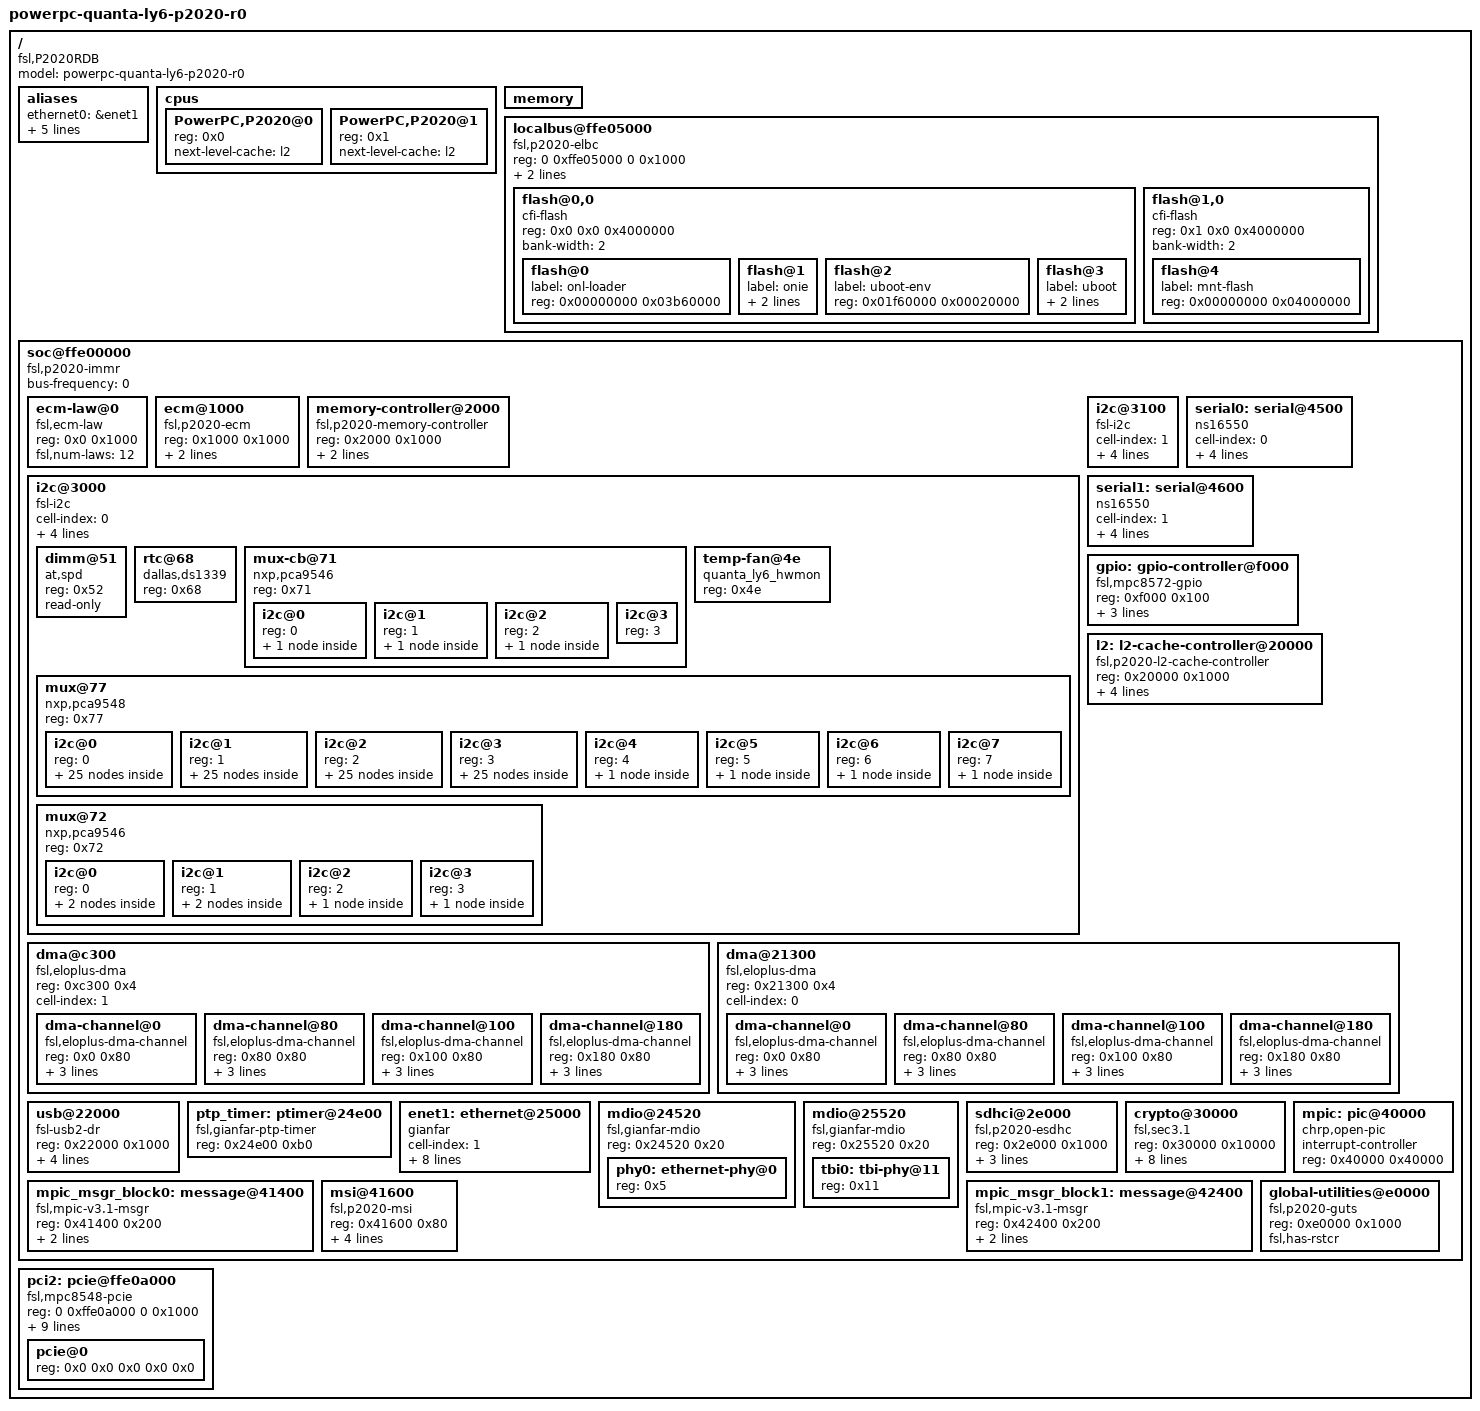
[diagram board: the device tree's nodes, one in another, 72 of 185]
/*
 * <bsn.cl fy=2013 v=gpl>
 * 
 *		Copyright 2013, 2014 BigSwitch Networks, Inc.		
 * 
 * This program is free software; you can redistribute it
 * and/or modify it under  the terms ofthe GNU General Public License as
 * published by the Free Software Foundation;  either version 2 of the  License,
 * or (at your option) any later version.
 * 
 * 
 * </bsn.cl>
 *
 *
 * Device tree for the Quanta LY6 P2020.
 *
 */


/dts-v1/;

/ {
	model = "powerpc-quanta-ly6-p2020-r0";
	compatible = "fsl,P2020RDB";
	#address-cells = <2>;
	#size-cells = <2>;

	aliases {
		ethernet0 = &enet1;
		serial0 = &serial0;
		serial1 = &serial1;
		pci2 = &pci2;
		mpic-msgr-block0 = &mpic_msgr_block0;
		mpic-msgr-block1 = &mpic_msgr_block1;
	};

	cpus {
		#address-cells = <1>;
		#size-cells = <0>;

		PowerPC,P2020@0 {
			device_type = "cpu";
			reg = <0x0>;
			next-level-cache = <&l2>;
		};

		PowerPC,P2020@1 {
			device_type = "cpu";
			reg = <0x1>;
			next-level-cache = <&l2>;
		};
	};

	memory {
		device_type = "memory";
	};

	localbus@ffe05000 {
		#address-cells = <2>;
		#size-cells = <1>;
		compatible = "fsl,p2020-elbc", "fsl,elbc", "simple-bus";
		reg = <0 0xffe05000 0 0x1000>;
		interrupts = <19 2>;
		interrupt-parent = <&mpic>;

		ranges = <0x0 0x0 0x0 0xec000000 0x4000000
			  0x1 0x0 0x0 0xe8000000 0x4000000>;

		flash@0,0 {
			#address-cells = <1>;
			#size-cells = <1>;
			compatible = "cfi-flash";
			reg = <0x0 0x0 0x4000000>;
			bank-width = <2>;

			/*
 			 * ONIE flash layout (reverse-engineered:
			 * - one ~64MiB loader partition
			 * - 4 MiB onie partition
			 * - uboot-env and uboot
			 * - 64MiB leftover space for jffs2
			 *
			 */

			flash@0 {
				label = "onl-loader";
				reg = <0x00000000 0x03b60000>;
			};

			flash@1 {
				label = "onie";
				reg = <0x01b60000 0x00400000>;
				read-only;
			};

			flash@2 {
				label = "uboot-env";
				reg = <0x01f60000 0x00020000>;
			};

			flash@3 {
				label = "uboot";
				reg = <0x01f80000 0x00080000>;
				read-only;
			};

		};

		flash@1,0 {
			#address-cells = <1>;
			#size-cells = <1>;
			compatible = "cfi-flash";
			reg = <0x1 0x0 0x4000000>;
			bank-width = <2>;

			flash@4 {
				label = "mnt-flash";
				reg = <0x00000000 0x04000000>;
			};
		};
	};

	soc@ffe00000 {
		#address-cells = <1>;
		#size-cells = <1>;
		device_type = "soc";
		compatible = "fsl,p2020-immr", "simple-bus";
		ranges = <0x0  0x0 0xffe00000 0x100000>;
		bus-frequency = <0>;

		ecm-law@0 {
			compatible = "fsl,ecm-law";
			reg = <0x0 0x1000>;
			fsl,num-laws = <12>;
		};

		ecm@1000 {
			compatible = "fsl,p2020-ecm", "fsl,ecm";
			reg = <0x1000 0x1000>;
			interrupts = <17 2>;
			interrupt-parent = <&mpic>;
		};

		memory-controller@2000 {
			compatible = "fsl,p2020-memory-controller";
			reg = <0x2000 0x1000>;
			interrupt-parent = <&mpic>;
			interrupts = <18 2>;
		};

		i2c@3000 {
			#address-cells = <1>;
			#size-cells = <0>;
			cell-index = <0>;
			compatible = "fsl-i2c";
			reg = <0x3000 0x100>;
			interrupts = <43 2>;
			interrupt-parent = <&mpic>;
			dfsrr;

			dimm@51 {
				compatible = "at,spd";
				reg = <0x52>;
				read-only;
			};

			rtc@68 {
				compatible = "dallas,ds1339";
				reg = <0x68>;
			};

			mux-cb@71 {
				compatible = "nxp,pca9546";
				reg = <0x71>;
				#address-cells = <1>;
				#size-cells = <0>;

				i2c@0 {
					#address-cells = <1>;
					#size-cells = <0>;
					reg = <0>;

					gpio-cb-9555@20 {
						compatible = "nxp,pca9555";
						reg = <0x20>;
						#gpio-cells = <2>;
						gpio-controller;
					};
				};

				i2c@1 {
					#address-cells = <1>;
					#size-cells = <0>;
					reg = <1>;

					eeprom-cb@53 {
						compatible = "at,24c02";
						reg = <0x53>;
						read-only;
					};
				};

				i2c@2 {
					#address-cells = <1>;
					#size-cells = <0>;
					reg = <2>;

					gpio-cb-9554@21 {
						compatible = "nxp,pca9554";
						reg = <0x21>;
						#gpio-cells = <2>;
						gpio-controller;
					};
				};

				i2c@3 {
					#address-cells = <1>;
					#size-cells = <0>;
					reg = <3>;
				};
			};

			temp-fan@4e {
				compatible = "quanta_ly6_hwmon";
				reg = <0x4e>;
			};

			mux@77 {
				compatible = "nxp,pca9548";
				reg = <0x77>;
				#address-cells = <1>;
				#size-cells = <0>;

				i2c@0 {
					#address-cells = <1>;
					#size-cells = <0>;
					reg = <0>;

					mux@73 {
						compatible = "nxp,pca9548";
						reg = <0x73>;
						#address-cells = <1>;
						#size-cells = <0>;

						i2c@0 {
							#address-cells = <1>;
							#size-cells = <0>;
							reg = <0>;

							qsfp-eeprom-1@50 {
								compatible = "at,24c02";
								reg = <0x50>;
								read-only;
							};
							qsfp-eeprom-1@51 {
								compatible = "at,24c02";
								reg = <0x51>;
								read-only;
							};
						};

						i2c@1 {
							#address-cells = <1>;
							#size-cells = <0>;
							reg = <1>;

							qsfp-eeprom-2@50 {
								compatible = "at,24c02";
								reg = <0x50>;
								read-only;
							};
							qsfp-eeprom-2@51 {
								compatible = "at,24c02";
								reg = <0x51>;
								read-only;
							};
						};

						i2c@2 {
							#address-cells = <1>;
							#size-cells = <0>;
							reg = <2>;

							qsfp-eeprom-3@50 {
								compatible = "at,24c02";
								reg = <0x50>;
								read-only;
							};
							qsfp-eeprom-3@51 {
								compatible = "at,24c02";
								reg = <0x51>;
								read-only;
							};
						};

						i2c@3 {
							#address-cells = <1>;
							#size-cells = <0>;
							reg = <3>;

							qsfp-eeprom-4@50 {
								compatible = "at,24c02";
								reg = <0x50>;
								read-only;
							};
							qsfp-eeprom-4@51 {
								compatible = "at,24c02";
								reg = <0x51>;
								read-only;
							};
						};

						i2c@4 {
							#address-cells = <1>;
							#size-cells = <0>;
							reg = <4>;

							qsfp-eeprom-5@50 {
								compatible = "at,24c02";
								reg = <0x50>;
								read-only;
							};
							qsfp-eeprom-5@51 {
								compatible = "at,24c02";
								reg = <0x51>;
								read-only;
							};
						};

						i2c@5 {
							#address-cells = <1>;
							#size-cells = <0>;
							reg = <5>;

							qsfp-eeprom-6@50 {
								compatible = "at,24c02";
								reg = <0x50>;
								read-only;
							};
							qsfp-eeprom-6@51 {
								compatible = "at,24c02";
								reg = <0x51>;
								read-only;
							};
						};

						i2c@6 {
							#address-cells = <1>;
							#size-cells = <0>;
							reg = <6>;

							qsfp-eeprom-7@50 {
								compatible = "at,24c02";
								reg = <0x50>;
								read-only;
							};
							qsfp-eeprom-7@51 {
								compatible = "at,24c02";
								reg = <0x51>;
								read-only;
							};
						};

						i2c@7 {
							#address-cells = <1>;
							#size-cells = <0>;
							reg = <7>;

							qsfp-eeprom-8@50 {
								compatible = "at,24c02";
								reg = <0x50>;
								read-only;
							};
							qsfp-eeprom-8@51 {
								compatible = "at,24c02";
								reg = <0x51>;
								read-only;
							};
						};
					};
				};

				i2c@1 {
					#address-cells = <1>;
					#size-cells = <0>;
					reg = <1>;

					mux@74 {
						compatible = "nxp,pca9548";
						reg = <0x74>;
						#address-cells = <1>;
						#size-cells = <0>;

						i2c@0 {
							#address-cells = <1>;
							#size-cells = <0>;
							reg = <0>;

							qsfp-eeprom-9@50 {
								compatible = "at,24c02";
								reg = <0x50>;
								read-only;
							};
							qsfp-eeprom-9@51 {
								compatible = "at,24c02";
								reg = <0x51>;
								read-only;
							};
						};

						i2c@1 {
							#address-cells = <1>;
							#size-cells = <0>;
							reg = <1>;

							qsfp-eeprom-10@50 {
								compatible = "at,24c02";
								reg = <0x50>;
								read-only;
							};
							qsfp-eeprom-10@51 {
								compatible = "at,24c02";
								reg = <0x51>;
								read-only;
							};
						};

						i2c@2 {
							#address-cells = <1>;
							#size-cells = <0>;
							reg = <2>;

							qsfp-eeprom-11@50 {
								compatible = "at,24c02";
								reg = <0x50>;
								read-only;
							};
							qsfp-eeprom-11@51 {
								compatible = "at,24c02";
								reg = <0x51>;
								read-only;
							};
						};

						i2c@3 {
							#address-cells = <1>;
							#size-cells = <0>;
							reg = <3>;

							qsfp-eeprom-12@50 {
								compatible = "at,24c02";
								reg = <0x50>;
								read-only;
							};
							qsfp-eeprom-12@51 {
								compatible = "at,24c02";
								reg = <0x51>;
								read-only;
							};
						};

						i2c@4 {
							#address-cells = <1>;
							#size-cells = <0>;
							reg = <4>;

							qsfp-eeprom-13@50 {
								compatible = "at,24c02";
								reg = <0x50>;
								read-only;
							};
							qsfp-eeprom-13@51 {
								compatible = "at,24c02";
								reg = <0x51>;
								read-only;
							};
						};

						i2c@5 {
							#address-cells = <1>;
							#size-cells = <0>;
							reg = <5>;

							qsfp-eeprom-14@50 {
								compatible = "at,24c02";
								reg = <0x50>;
								read-only;
							};
							qsfp-eeprom-14@51 {
								compatible = "at,24c02";
								reg = <0x51>;
								read-only;
							};
						};

						i2c@6 {
							#address-cells = <1>;
							#size-cells = <0>;
							reg = <6>;

							qsfp-eeprom-15@50 {
								compatible = "at,24c02";
								reg = <0x50>;
								read-only;
							};
							qsfp-eeprom-15@51 {
								compatible = "at,24c02";
								reg = <0x51>;
								read-only;
							};
						};

						i2c@7 {
							#address-cells = <1>;
							#size-cells = <0>;
							reg = <7>;

							qsfp-eeprom-16@50 {
								compatible = "at,24c02";
								reg = <0x50>;
								read-only;
							};
							qsfp-eeprom-16@51 {
								compatible = "at,24c02";
								reg = <0x51>;
								read-only;
							};
						};
					};
				};

				i2c@2 {
					#address-cells = <1>;
					#size-cells = <0>;
					reg = <2>;

					mux@75 {
						compatible = "nxp,pca9548";
						reg = <0x75>;
						#address-cells = <1>;
						#size-cells = <0>;

						i2c@0 {
							#address-cells = <1>;
							#size-cells = <0>;
							reg = <0>;

							qsfp-eeprom-17@50 {
								compatible = "at,24c02";
								reg = <0x50>;
								read-only;
							};
							qsfp-eeprom-17@51 {
								compatible = "at,24c02";
								reg = <0x51>;
								read-only;
							};
						};

						i2c@1 {
							#address-cells = <1>;
							#size-cells = <0>;
							reg = <1>;

							qsfp-eeprom-18@50 {
								compatible = "at,24c02";
								reg = <0x50>;
								read-only;
							};
							qsfp-eeprom-18@51 {
								compatible = "at,24c02";
								reg = <0x51>;
								read-only;
							};
						};

						i2c@2 {
							#address-cells = <1>;
							#size-cells = <0>;
							reg = <2>;

							qsfp-eeprom-19@50 {
								compatible = "at,24c02";
								reg = <0x50>;
								read-only;
							};
							qsfp-eeprom-19@51 {
								compatible = "at,24c02";
								reg = <0x51>;
								read-only;
							};
						};

						i2c@3 {
							#address-cells = <1>;
							#size-cells = <0>;
							reg = <3>;

							qsfp-eeprom-20@50 {
								compatible = "at,24c02";
								reg = <0x50>;
								read-only;
							};
							qsfp-eeprom-20@51 {
								compatible = "at,24c02";
								reg = <0x51>;
								read-only;
							};
						};

						i2c@4 {
							#address-cells = <1>;
							#size-cells = <0>;
							reg = <4>;

							qsfp-eeprom-21@50 {
								compatible = "at,24c02";
								reg = <0x50>;
								read-only;
							};
							qsfp-eeprom-21@51 {
								compatible = "at,24c02";
								reg = <0x51>;
								read-only;
							};
						};

						i2c@5 {
							#address-cells = <1>;
							#size-cells = <0>;
							reg = <5>;

							qsfp-eeprom-22@50 {
								compatible = "at,24c02";
								reg = <0x50>;
								read-only;
							};
							qsfp-eeprom-22@51 {
								compatible = "at,24c02";
								reg = <0x51>;
								read-only;
							};
						};

						i2c@6 {
							#address-cells = <1>;
							#size-cells = <0>;
							reg = <6>;

							qsfp-eeprom-23@50 {
								compatible = "at,24c02";
								reg = <0x50>;
								read-only;
							};
							qsfp-eeprom-23@51 {
								compatible = "at,24c02";
								reg = <0x51>;
								read-only;
							};
						};

						i2c@7 {
							#address-cells = <1>;
							#size-cells = <0>;
							reg = <7>;

							qsfp-eeprom-24@50 {
								compatible = "at,24c02";
								reg = <0x50>;
								read-only;
							};
							qsfp-eeprom-24@51 {
								compatible = "at,24c02";
								reg = <0x51>;
								read-only;
							};
						};
					};
				};

				i2c@3 {
					#address-cells = <1>;
					#size-cells = <0>;
					reg = <3>;

					mux@76 {
						compatible = "nxp,pca9548";
						reg = <0x76>;
						#address-cells = <1>;
						#size-cells = <0>;

						i2c@0 {
							#address-cells = <1>;
							#size-cells = <0>;
							reg = <0>;

							qsfp-eeprom-25@50 {
								compatible = "at,24c02";
								reg = <0x50>;
								read-only;
							};
							qsfp-eeprom-25@51 {
								compatible = "at,24c02";
								reg = <0x51>;
								read-only;
							};
						};

						i2c@1 {
							#address-cells = <1>;
							#size-cells = <0>;
							reg = <1>;

							qsfp-eeprom-26@50 {
								compatible = "at,24c02";
								reg = <0x50>;
								read-only;
							};
							qsfp-eeprom-26@51 {
								compatible = "at,24c02";
								reg = <0x51>;
								read-only;
							};
						};

						i2c@2 {
							#address-cells = <1>;
							#size-cells = <0>;
							reg = <2>;

							qsfp-eeprom-27@50 {
								compatible = "at,24c02";
								reg = <0x50>;
								read-only;
							};
							qsfp-eeprom-27@51 {
								compatible = "at,24c02";
								reg = <0x51>;
								read-only;
							};
						};

						i2c@3 {
							#address-cells = <1>;
							#size-cells = <0>;
							reg = <3>;

							qsfp-eeprom-28@50 {
								compatible = "at,24c02";
								reg = <0x50>;
								read-only;
							};
							qsfp-eeprom-28@51 {
								compatible = "at,24c02";
								reg = <0x51>;
								read-only;
							};
						};

						i2c@4 {
							#address-cells = <1>;
							#size-cells = <0>;
							reg = <4>;

							qsfp-eeprom-29@50 {
								compatible = "at,24c02";
								reg = <0x50>;
								read-only;
							};
							qsfp-eeprom-29@51 {
								compatible = "at,24c02";
								reg = <0x51>;
								read-only;
							};
						};

						i2c@5 {
							#address-cells = <1>;
							#size-cells = <0>;
							reg = <5>;

							qsfp-eeprom-30@50 {
								compatible = "at,24c02";
								reg = <0x50>;
								read-only;
							};
							qsfp-eeprom-30@51 {
								compatible = "at,24c02";
								reg = <0x51>;
								read-only;
							};
						};

						i2c@6 {
							#address-cells = <1>;
							#size-cells = <0>;
							reg = <6>;

							qsfp-eeprom-31@50 {
								compatible = "at,24c02";
								reg = <0x50>;
								read-only;
							};
							qsfp-eeprom-31@51 {
								compatible = "at,24c02";
								reg = <0x51>;
								read-only;
							};
						};

						i2c@7 {
							#address-cells = <1>;
							#size-cells = <0>;
							reg = <7>;

							qsfp-eeprom-32@50 {
								compatible = "at,24c02";
								reg = <0x50>;
								read-only;
							};
							qsfp-eeprom-32@51 {
								compatible = "at,24c02";
								reg = <0x51>;
								read-only;
							};
						};
					};
				};

				i2c@4 {
					#address-cells = <1>;
					#size-cells = <0>;
					reg = <4>;

					mux-cpld-2@3a {
						compatible = "quanta_ly6_i2c_mux";
						reg = <0x3a>;
						#address-cells = <1>;
						#size-cells = <0>;
					};
				};

				i2c@5 {
					#address-cells = <1>;
					#size-cells = <0>;
					reg = <5>;

					mux-cpld-3@3b {
						compatible = "quanta_ly6_i2c_mux";
						reg = <0x3b>;
						#address-cells = <1>;
						#size-cells = <0>;
					};
				};

				i2c@6 {
					#address-cells = <1>;
					#size-cells = <0>;
					reg = <6>;

					gpio-1@24 {
						compatible = "nxp,pca9555";
						reg = <0x24>;
						#gpio-cells = <2>;
						gpio-controller;
					};
				};

				i2c@7 {
					#address-cells = <1>;
					#size-cells = <0>;
					reg = <7>;

					gpio-2@23 {
						compatible = "nxp,pca9555";
						reg = <0x23>;
						#gpio-cells = <2>;
						gpio-controller;
					};
				};
			};

			mux@72 {
				compatible = "nxp,pca9546";
				reg = <0x72>;
				#address-cells = <1>;
				#size-cells = <0>;

				i2c@0 {
					#address-cells = <1>;
					#size-cells = <0>;
					reg = <0>;

					psu-1@58 {
						compatible = "pmbus";
						reg = <0x58>;
					};

					psu-1@69 {
						compatible = "pmbus";
						reg = <0x69>;
					};
				};

				i2c@1 {
					#address-cells = <1>;
					#size-cells = <0>;
					reg = <1>;

					psu-2@59 {
						compatible = "pmbus";
						reg = <0x59>;
					};

					psu-2@6f {
						compatible = "pmbus";
						reg = <0x6f>;
					};
				};

				i2c@2 {
					#address-cells = <1>;
					#size-cells = <0>;
					reg = <2>;

					gpio-psu-1@26 {
						compatible = "nxp,pca9555";
						reg = <0x26>;
						#gpio-cells = <2>;
						gpio-controller;
					};
				};

				i2c@3 {
					#address-cells = <1>;
					#size-cells = <0>;
					reg = <3>;

					eeprom-mb@54 {
						compatible = "at,24c02";
						reg = <0x54>;
						read-only;
					};
				};
			};
		};

		i2c@3100 {
			#address-cells = <1>;
			#size-cells = <0>;
			cell-index = <1>;
			compatible = "fsl-i2c";
			reg = <0x3100 0x100>;
			interrupts = <43 2>;
			interrupt-parent = <&mpic>;
			dfsrr;
		};

		serial0: serial@4500 {
			cell-index = <0>;
			device_type = "serial";
			compatible = "ns16550";
			reg = <0x4500 0x100>;
			clock-frequency = <0>;
			interrupts = <42 2>;
			interrupt-parent = <&mpic>;
		};

		serial1: serial@4600 {
			cell-index = <1>;
			device_type = "serial";
			compatible = "ns16550";
			reg = <0x4600 0x100>;
			clock-frequency = <0>;
			interrupts = <42 2>;
			interrupt-parent = <&mpic>;
		};

		dma@c300 {
			#address-cells = <1>;
			#size-cells = <1>;
			compatible = "fsl,eloplus-dma";
			reg = <0xc300 0x4>;
			ranges = <0x0 0xc100 0x200>;
			cell-index = <1>;
			dma-channel@0 {
				compatible = "fsl,eloplus-dma-channel";
				reg = <0x0 0x80>;
				cell-index = <0>;
				interrupt-parent = <&mpic>;
				interrupts = <76 2>;
			};
			dma-channel@80 {
				compatible = "fsl,eloplus-dma-channel";
				reg = <0x80 0x80>;
				cell-index = <1>;
				interrupt-parent = <&mpic>;
				interrupts = <77 2>;
			};
			dma-channel@100 {
				compatible = "fsl,eloplus-dma-channel";
				reg = <0x100 0x80>;
				cell-index = <2>;
				interrupt-parent = <&mpic>;
				interrupts = <78 2>;
			};
			dma-channel@180 {
				compatible = "fsl,eloplus-dma-channel";
				reg = <0x180 0x80>;
				cell-index = <3>;
				interrupt-parent = <&mpic>;
				interrupts = <79 2>;
			};
		};

		gpio: gpio-controller@f000 {
			#gpio-cells = <2>;
			compatible = "fsl,mpc8572-gpio";
			reg = <0xf000 0x100>;
			interrupts = <47 0x2>;
			interrupt-parent = <&mpic>;
			gpio-controller;
		};

		l2: l2-cache-controller@20000 {
			compatible = "fsl,p2020-l2-cache-controller";
			reg = <0x20000 0x1000>;
			cache-line-size = <32>;	// 32 bytes
			cache-size = <0x80000>; // L2,512K
			interrupt-parent = <&mpic>;
			interrupts = <16 2>;
		};

		dma@21300 {
			#address-cells = <1>;
			#size-cells = <1>;
			compatible = "fsl,eloplus-dma";
			reg = <0x21300 0x4>;
			ranges = <0x0 0x21100 0x200>;
			cell-index = <0>;
			dma-channel@0 {
				compatible = "fsl,eloplus-dma-channel";
				reg = <0x0 0x80>;
				cell-index = <0>;
				interrupt-parent = <&mpic>;
				interrupts = <20 2>;
			};
			dma-channel@80 {
				compatible = "fsl,eloplus-dma-channel";
				reg = <0x80 0x80>;
				cell-index = <1>;
				interrupt-parent = <&mpic>;
				interrupts = <21 2>;
			};
			dma-channel@100 {
				compatible = "fsl,eloplus-dma-channel";
				reg = <0x100 0x80>;
				cell-index = <2>;
				interrupt-parent = <&mpic>;
				interrupts = <22 2>;
			};
			dma-channel@180 {
				compatible = "fsl,eloplus-dma-channel";
				reg = <0x180 0x80>;
				cell-index = <3>;
				interrupt-parent = <&mpic>;
				interrupts = <23 2>;
			};
		};

		usb@22000 {
			#address-cells = <1>;
			#size-cells = <0>;
			compatible = "fsl-usb2-dr";
			reg = <0x22000 0x1000>;
			interrupt-parent = <&mpic>;
			interrupts = <28 0x2>;
			phy_type = "ulpi";
			dr_mode = "host";
		};

		ptp_timer: ptimer@24e00 {
			compatible = "fsl,gianfar-ptp-timer";
			reg = <0x24e00 0xb0>;
		};

		enet1: ethernet@25000 {
			#address-cells = <1>;
			#size-cells = <1>;
			cell-index = <1>;
			device_type = "network";
			model = "eTSEC";
			compatible = "gianfar";
			reg = <0x25000 0x1000>;
			ranges = <0x0 0x25000 0x1000>;
			local-mac-address = [ 00 c0 9f 01 02 03 ];
			interrupts = <35 2 36 2 40 2>;
			interrupt-parent = <&mpic>;
			phy-connection-type = "sgmii";
			phy-handle = <&phy0>;
			tbi-handle = <&tbi0>;
		};

		mdio@24520 {
			#address-cells = <1>;
			#size-cells = <0>;
			compatible = "fsl,gianfar-mdio";
			reg = <0x24520 0x20>;
			phy0: ethernet-phy@0 {
				reg = <0x5>;
				device_type = "ethernet-phy";
			};
		};

		mdio@25520 {
			#address-cells = <1>;
			#size-cells = <0>;
			compatible = "fsl,gianfar-mdio";
			reg = <0x25520 0x20>;

			tbi0: tbi-phy@11 {
				reg = <0x11>;
				device_type = "tbi-phy";
			};
		};

		sdhci@2e000 {
			compatible = "fsl,p2020-esdhc", "fsl,esdhc";
			reg = <0x2e000 0x1000>;
			interrupts = <72 0x2>;
			interrupt-parent = <&mpic>;
			clock-frequency = <0>;
		};

		crypto@30000 {
			compatible = "fsl,sec3.1", "fsl,sec3.0", "fsl,sec2.4",
					 "fsl,sec2.2", "fsl,sec2.1", "fsl,sec2.0";
			reg = <0x30000 0x10000>;
			interrupts = <45 2 58 2>;
			interrupt-parent = <&mpic>;
			fsl,num-channels = <4>;
			fsl,channel-fifo-len = <24>;
			fsl,exec-units-mask = <0xbfe>;
			fsl,descriptor-types-mask = <0x3ab0ebf>;
			fsl,multi-host-mode = "dual";
			fsl,channel-remap = <0x3>;
		};

		mpic: pic@40000 {
			interrupt-controller;
			#address-cells = <0>;
			#interrupt-cells = <2>;
			reg = <0x40000 0x40000>;
			compatible = "chrp,open-pic";
			device_type = "open-pic";
		};

		mpic_msgr_block0: message@41400 {
			compatible = "fsl,mpic-v3.1-msgr";
			reg = <0x41400 0x200>;
			interrupts = <
				0xb0 2
				0xb1 2
				0xb2 2
				0xb3 2>;
			interrupt-parent = <&mpic>;
		};

		mpic_msgr_block1: message@42400 {
			compatible = "fsl,mpic-v3.1-msgr";
			reg = <0x42400 0x200>;
			interrupts = <
				0xb4 2
				0xb5 2
				0xb6 2
				0xb7 2>;
			interrupt-parent = <&mpic>;
		};

		msi@41600 {
			compatible = "fsl,p2020-msi", "fsl,mpic-msi";
			reg = <0x41600 0x80>;
			msi-available-ranges = <0 0x100>;
			interrupts = <
				0xe0 0
				0xe1 0
				0xe2 0
				0xe3 0
				0xe4 0
				0xe5 0
				0xe6 0
				0xe7 0>;
			interrupt-parent = <&mpic>;
		};

		global-utilities@e0000 {
			compatible = "fsl,p2020-guts";
			reg = <0xe0000 0x1000>;
			fsl,has-rstcr;
		};
	};

	pci2: pcie@ffe0a000 {
		compatible = "fsl,mpc8548-pcie";
		device_type = "pci";
		#interrupt-cells = <1>;
		#size-cells = <2>;
		#address-cells = <3>;
		reg = <0 0xffe0a000 0 0x1000>;
		bus-range = <0 255>;
		ranges = <0x2000000 0x0 0xc0000000 0 0xc0000000 0x0 0x20000000
			  0x1000000 0x0 0x00000000 0 0xffc20000 0x0 0x10000>;
		clock-frequency = <100000000>;
		interrupt-parent = <&mpic>;
		interrupts = <26 2>;
		interrupt-map-mask = <0xf800 0x0 0x0 0x7>;
		interrupt-map = <
			/* IDSEL 0x0 */
			0000 0x0 0x0 0x1 &mpic 0x0 0x1
			0000 0x0 0x0 0x2 &mpic 0x1 0x1
			0000 0x0 0x0 0x3 &mpic 0x2 0x1
			0000 0x0 0x0 0x4 &mpic 0x3 0x1
			>;
		pcie@0 {
			reg = <0x0 0x0 0x0 0x0 0x0>;
			#size-cells = <2>;
			#address-cells = <3>;
			device_type = "pci";
			ranges = <0x2000000 0x0 0xc0000000
				  0x2000000 0x0 0xc0000000
				  0x0 0x20000000

				  0x1000000 0x0 0x0
				  0x1000000 0x0 0x0
				  0x0 0x10000>;
		};
	};
};
